# ATmega4809 register map
Vendor: Atmel; File version: 1.0
CPU: other r0p0, little endian, no MPU, no FPU, 4 interrupt priority bits
Registers are 8-bit, read-write, reset 0x0 unless marked. A register's access mark holds for its fields unless they carry their own. Offsets are from the block's base; [hi:lo] are bit positions; {n}, {i} and the like mark numbered series.

## GPIO — General Purpose IO
Base 0x0080001C
{0x0+i} GPIOR{i} (i=0..3) — General Purpose IO Register {i}

## LOCKBIT
Base 0x0080128A
0x00 LOCKBIT — Lock Bits
  [7:0] LB
    58=RWLOCK (Read and write lock); 197=NOLOCK (No locks)

## NVMCTRL — Non-volatile Memory Controller
Base 0x00801000
0x00 CTRLA — Control A
  [2:0] CMD — Command
    0=NONE (No Command); 1=PAGEWRITE (Write page); 2=PAGEERASE (Erase page); 3=PAGEERASEWRITE (Erase and write page); 4=PAGEBUFCLR (Page buffer clear); 5=CHIPERASE; 6=EEERASE (EEPROM erase); 7=FUSEWRITE (Write fuse (PDI only))
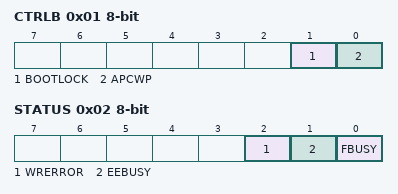
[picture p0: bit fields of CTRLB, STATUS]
0x01 CTRLB — Control B
  [1] BOOTLOCK
  [0] APCWP — Application code write protect
0x02 STATUS ro
  [2] WRERROR — Write error
  [1] EEBUSY — EEPROM busy
  [0] FBUSY — Flash busy
0x03 INTCTRL — Interrupt Control
  [0] EEREADY — EEPROM Ready
0x04 INTFLAGS — Interrupt Flags
  [0] EEREADY — EEPROM Ready
0x06 DATA 16-bit (reset mask 0xFF)
0x08 ADDR 16-bit (reset mask 0xFF) — Address

## PORTMUX — Port Multiplexer
Base 0x008005E0
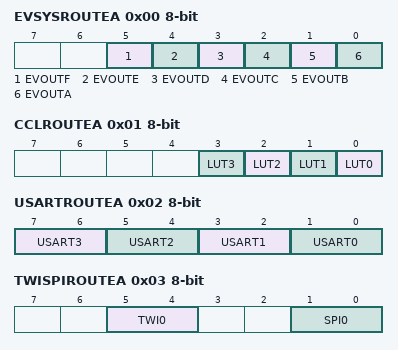
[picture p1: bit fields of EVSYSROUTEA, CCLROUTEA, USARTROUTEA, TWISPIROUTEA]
0x00 EVSYSROUTEA — Port Multiplexer EVSYS
  [5] EVOUTF — Event Output F
    0=DEFAULT (EVOUT on PF2)
  [4] EVOUTE — Event Output E
    0=DEFAULT (EVOUT on PE2)
  [3] EVOUTD — Event Output D
    0=DEFAULT (EVOUT on PD2); 1=ALT1 (EVOUT on PD7)
  [2] EVOUTC — Event Output C
    0=DEFAULT (EVOUT on PC2); 1=ALT1 (EVOUT on PC7)
  [1] EVOUTB — Event Output B
    0=DEFAULT (EVOUT on PB2)
  [0] EVOUTA — Event Output A
    0=DEFAULT (EVOUT on PA2); 1=ALT1 (EVOUT on PA7)
0x01 CCLROUTEA — Port Multiplexer CCL
  [n] LUT{n} (n=0..3) — CCL LUT{n}
0x02 USARTROUTEA — Port Multiplexer USART register A
  [7:6] USART3 — Port Multiplexer USART3
    0=DEFAULT (USART3 on PB[3:0]); 1=ALT1 (USART3 on PB[5:4]); 3=NONE (Not connected to any pins)
  [5:4] USART2 — Port Multiplexer USART2
    0=DEFAULT (USART2 on PF[3:0]); 1=ALT1 (USART2 on PF[6:4]); 3=NONE (Not connected to any pins)
  [3:2] USART1 — Port Multiplexer USART1
    0=DEFAULT (USART1 on PC[3:0]); 1=ALT1 (USART1 on PC[7:4]); 3=NONE (Not connected to any pins)
  [1:0] USART0 — Port Multiplexer USART0
    0=DEFAULT (USART0 on PA[3:0]); 1=ALT1 (USART0 on PA[7:4]); 3=NONE (Not connected to any pins)
0x03 TWISPIROUTEA — Port Multiplexer TWI and SPI
  [5:4] TWI0 — Port Multiplexer TWI0
    0=DEFAULT (SCL/SDA on PA[3:2], Client mode on PC[3:2] in dual TWI mode); 1=ALT1 (SCL/SDA on PA[3:2], Client mode on PF[3:2] in dual TWI mode); 2=ALT2 (SCL/SDA on PC[3:2], Client mode on PF[3:2] in dual TWI mode); 3=NONE (Not connected to any pins)
  [1:0] SPI0 — Port Multiplexer SPI0
    0=DEFAULT (SPI0 on PA[7:4]); 1=ALT1 (SPI0 on PC[3:0]); 2=ALT2 (SPI0 on PE[3:0]); 3=NONE (Not connected to any pins)
0x04 TCAROUTEA — Port Multiplexer TCA
  [2:0] TCA0 — Port Multiplexer TCA0
    0=PORTA (TCA0 pins on PA[5:0]); 1=PORTB (TCA0 pins on PB[5:0]); 2=PORTC (TCA0 pins on PC[5:0]); 3=PORTD (TCA0 pins on PD[5:0]); 4=PORTE (TCA0 pins on PE[5:0]); 5=PORTF (TCA0 pins on PF[5:0])
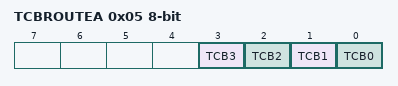
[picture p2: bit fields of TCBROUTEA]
0x05 TCBROUTEA — Port Multiplexer TCB
  [3] TCB3 — Port Multiplexer TCB3
    0=DEFAULT (WO on PB5); 1=ALT1 (WO on PC1)
  [2] TCB2 — Port Multiplexer TCB2
    0=DEFAULT (WO on PC0); 1=ALT1 (WO on PB4)
  [1] TCB1 — Port Multiplexer TCB1
    0=DEFAULT (WO on PA3); 1=ALT1 (WO on PF5)
  [0] TCB0 — Port Multiplexer TCB0
    0=DEFAULT (WO on PA2); 1=ALT1 (WO on PF4)

## RSTCTRL — Reset controller
Base 0x00800040
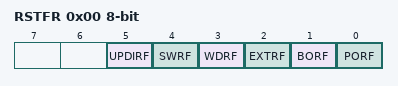
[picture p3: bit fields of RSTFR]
0x00 RSTFR — Reset Flags
  [5] UPDIRF — UPDI Reset flag
  [4] SWRF — Software Reset flag
  [3] WDRF — Watch dog Reset flag
  [2] EXTRF — External Reset flag
  [1] BORF — Brown out detector Reset flag
  [0] PORF — Power on Reset flag
0x01 SWRR — Software Reset
  [0] SWRE — Software reset enable
